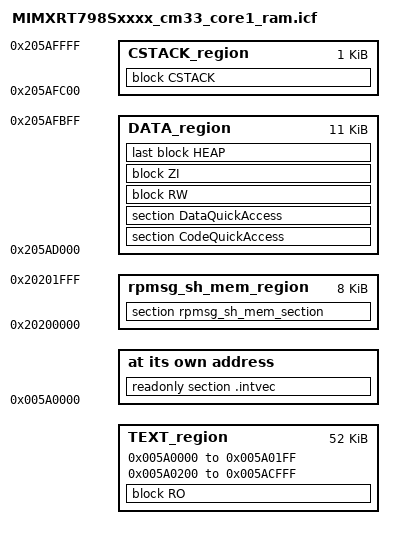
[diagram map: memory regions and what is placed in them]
/*
** ###################################################################
**     Processors:          MIMXRT798SGAWAR_cm33_core1
**                          MIMXRT798SGFOA_cm33_core1
**
**     Compiler:            IAR ANSI C/C++ Compiler for ARM
**     Reference manual:    iMXRT700RM Rev.2 DraftA, 05/2024
**     Version:             rev. 2.0, 2024-05-28
**     Build:               b240528
**
**     Abstract:
**         Linker file for the IAR ANSI C/C++ Compiler for ARM
**
**     Copyright 2016 Freescale Semiconductor, Inc.
**     Copyright 2016-2024 NXP
**     SPDX-License-Identifier: BSD-3-Clause
**
**     http:                 www.nxp.com
**     mail:                 support@nxp.com
**
** ###################################################################
*/

/* Stack and Heap Sizes */
if (isdefinedsymbol(__stack_size__)) {
  define symbol __size_cstack__        = __stack_size__;
} else {
  define symbol __size_cstack__        = 0x0400;
}

if (isdefinedsymbol(__heap_size__)) {
  define symbol __size_heap__          = __heap_size__;
} else {
  define symbol __size_heap__          = 0x0400;
}

/* The SRAM region [0x580000-0x5BFFFF] is reserved for shared memory or application data. */
/* The SRAM region [0x5C0000-0x67FFFF] is reserved for CPU1 application. */
/* The SRAM region [0x680000-0x77FFFF] is reserved for HiFi1 application. */

define symbol m_interrupts_start               = 0x005A0000;
define symbol m_interrupts_end                 = 0x005A01FF;

define symbol m_text_start                     = 0x005A0200;
define symbol m_text_end                       = 0x005ACFFF;

define symbol m_data_start                     = 0x205AD000;
define symbol m_data_end                       = 0x205AFFFF;

define exported symbol __VECTOR_TABLE          = m_interrupts_start;
define exported symbol __VECTOR_RAM            = m_interrupts_start;
define exported symbol __RAM_VECTOR_TABLE_SIZE = 0x0;

if (isdefinedsymbol(__use_shmem__)) {
  define exported symbol rpmsg_sh_mem_start    = 0x20200000;
  define exported symbol rpmsg_sh_mem_end      = 0x20201FFF;
} else if (isdefinedsymbol(__use_shmem_hifi1__)) {
  define exported symbol rpmsg_sh_mem_start    = 0x20588000;
  define exported symbol rpmsg_sh_mem_end      = 0x20589FFF;
}

define memory mem with size = 4G;

define region TEXT_region             = mem:[from m_interrupts_start to m_interrupts_end]
                                      | mem:[from m_text_start to m_text_end];
define region DATA_region             = mem:[from m_data_start to m_data_end - __size_cstack__];
define region CSTACK_region           = mem:[from m_data_end-__size_cstack__ + 1 to m_data_end];
if (isdefinedsymbol(__use_shmem__)) {
  define region rpmsg_sh_mem_region   = mem:[from rpmsg_sh_mem_start to rpmsg_sh_mem_end];
}

define block CSTACK    with alignment = 8, size = __size_cstack__   { };
define block HEAP      with alignment = 8, size = __size_heap__     { };
define block RO        { readonly };
define block RW        { readwrite };
define block ZI        { zi };

initialize by copy { readwrite, section .textrw , section CodeQuickAccess, section DataQuickAccess };

do not initialize  { section .noinit };
if (isdefinedsymbol(__use_shmem__)) {
  do not initialize  { section rpmsg_sh_mem_section };
}

place at address mem: m_interrupts_start    { readonly section .intvec };
place in TEXT_region                        { block RO };
place in DATA_region                        { section CodeQuickAccess, section DataQuickAccess };
place in DATA_region                        { block RW };
place in DATA_region                        { block ZI };
place in DATA_region                        { last block HEAP };
place in CSTACK_region                      { block CSTACK };
if (isdefinedsymbol(__use_shmem__)) {
  place in rpmsg_sh_mem_region              { section rpmsg_sh_mem_section };
}
